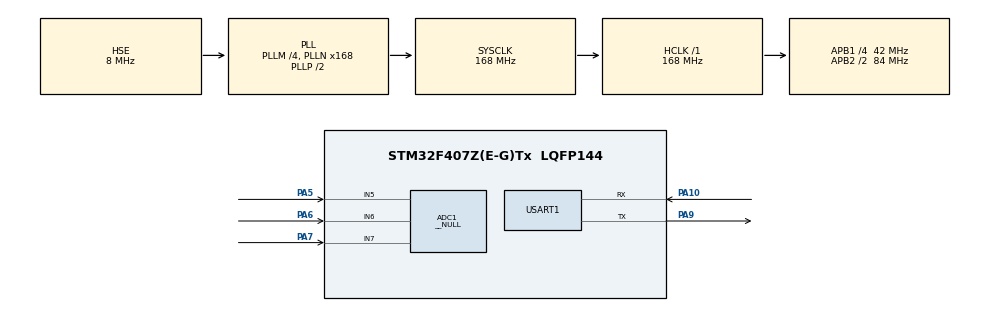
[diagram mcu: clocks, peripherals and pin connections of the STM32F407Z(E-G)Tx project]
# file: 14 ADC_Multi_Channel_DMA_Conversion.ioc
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ADC1.Channel-1\#ChannelRegularConversion=ADC_CHANNEL_5
ADC1.Channel-2\#ChannelRegularConversion=ADC_CHANNEL_6
ADC1.Channel-3\#ChannelRegularConversion=ADC_CHANNEL_7
ADC1.DMAContinuousRequests=ENABLE
ADC1.EOCSelection=ADC_EOC_SEQ_CONV
ADC1.ExternalTrigConv=ADC_EXTERNALTRIGCONV_T3_TRGO
ADC1.Mode=__NULL
ADC1.NbrOfConversion=3
ADC1.NbrOfConversionFlag=1
ADC1.Rank-1\#ChannelRegularConversion=1
ADC1.Rank-2\#ChannelRegularConversion=2
ADC1.Rank-3\#ChannelRegularConversion=3
ADC1.SamplingTime-1\#ChannelRegularConversion=ADC_SAMPLETIME_15CYCLES
ADC1.SamplingTime-2\#ChannelRegularConversion=ADC_SAMPLETIME_15CYCLES
ADC1.SamplingTime-3\#ChannelRegularConversion=ADC_SAMPLETIME_15CYCLES
ADC1.ScanConvMode=ENABLE
ADC1.master=1
Dma.ADC1.0.Direction=DMA_PERIPH_TO_MEMORY
Dma.ADC1.0.FIFOMode=DMA_FIFOMODE_DISABLE
Dma.ADC1.0.Instance=DMA2_Stream0
Dma.ADC1.0.MemDataAlignment=DMA_MDATAALIGN_WORD
Dma.ADC1.0.MemInc=DMA_MINC_ENABLE
Dma.ADC1.0.Mode=DMA_CIRCULAR
Dma.ADC1.0.PeriphDataAlignment=DMA_PDATAALIGN_WORD
Dma.ADC1.0.PeriphInc=DMA_PINC_DISABLE
Dma.ADC1.0.Priority=DMA_PRIORITY_MEDIUM
Dma.Request0=ADC1
Mcu.Family=STM32F4
Mcu.Name=STM32F407Z(E-G)Tx
Mcu.Package=LQFP144
NVIC.DMA2_Stream0_IRQn=true\:1\:0\:true\:false\:true\:true\:true\:true
NVIC.PriorityGroup=NVIC_PRIORITYGROUP_4
PA10.Mode=Asynchronous
PA10.Signal=USART1_RX
PA13.Mode=Serial_Wire
PA13.Signal=SYS_JTMS-SWDIO
PA14.Mode=Serial_Wire
PA14.Signal=SYS_JTCK-SWCLK
PA5.Signal=ADCx_IN5
PA6.Signal=ADCx_IN6
PA7.Signal=ADCx_IN7
PA9.Mode=Asynchronous
PA9.Signal=USART1_TX
PC14-OSC32_IN.Mode=LSE-External-Oscillator
PC14-OSC32_IN.Signal=RCC_OSC32_IN
PC15-OSC32_OUT.Mode=LSE-External-Oscillator
PC15-OSC32_OUT.Signal=RCC_OSC32_OUT
PH0-OSC_IN.Mode=HSE-External-Oscillator
PH0-OSC_IN.Signal=RCC_OSC_IN
PH1-OSC_OUT.Mode=HSE-External-Oscillator
PH1-OSC_OUT.Signal=RCC_OSC_OUT
ProjectManager.HeapSize=0x200
ProjectManager.StackSize=0x400
ProjectManager.TargetToolchain=MDK-ARM V5.32
RCC.48MHZClocksFreq_Value=84000000
RCC.AHBFreq_Value=168000000
RCC.APB1CLKDivider=RCC_HCLK_DIV4
RCC.APB1Freq_Value=42000000
RCC.APB1TimFreq_Value=84000000
RCC.APB2CLKDivider=RCC_HCLK_DIV2
RCC.APB2Freq_Value=84000000
RCC.APB2TimFreq_Value=168000000
RCC.CortexFreq_Value=168000000
RCC.HCLKFreq_Value=168000000
RCC.HSE_VALUE=8000000
RCC.HSI_VALUE=16000000
RCC.PLLM=4
RCC.PLLN=168
RCC.PLLSourceVirtual=RCC_PLLSOURCE_HSE
RCC.RCC_RTC_Clock_Source=RCC_RTCCLKSOURCE_LSE
RCC.RCC_RTC_Clock_SourceVirtual=RCC_RTCCLKSOURCE_LSE
RCC.SYSCLKFreq_VALUE=168000000
RCC.SYSCLKSource=RCC_SYSCLKSOURCE_PLLCLK
RCC.VCOOutputFreq_Value=336000000
SH.ADCx_IN5.0=ADC1_IN5,IN5
SH.ADCx_IN6.0=ADC1_IN6,IN6
SH.ADCx_IN7.0=ADC1_IN7,IN7
TIM3.Period=999
TIM3.Prescaler=8399
TIM3.TIM_MasterOutputTrigger=TIM_TRGO_UPDATE
USART1.VirtualMode=VM_ASYNC
VP_TIM3_VS_ClockSourceINT.Mode=Internal
board=custom

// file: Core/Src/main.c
/* USER CODE BEGIN Header */
/**
  ******************************************************************************
  * @file           : main.c
  * @brief          : Main program body
  ******************************************************************************
  * @attention
  *
  * Copyright (c) 2023 STMicroelectronics.
  * All rights reserved.
  *
  * This software is licensed under terms that can be found in the LICENSE file
  * in the root directory of this software component.
  * If no LICENSE file comes with this software, it is provided AS-IS.
  *
  ******************************************************************************
  */
/* USER CODE END Header */
#include "main.h"
#include "adc.h"
#include "dma.h"
#include "tim.h"
#include "usart.h"
#include "gpio.h"

/* USER CODE BEGIN PTD */
#include "stdio.h"

#ifdef __GNUC__
#define PUTCHAR_PROTOTYPE int __io_putchar(int ch)
#else
#define PUTCHAR_PROTOTYPE int fputc(int ch, FILE *f)
#endif
PUTCHAR_PROTOTYPE
{
      HAL_UART_Transmit(&huart1, (uint8_t *)&ch, 1, HAL_MAX_DELAY);
      return ch;
}
/* USER CODE END PTD */

/* USER CODE BEGIN PV */
uint32_t DataBuffer[BATCH_DATA_LEN];
/* USER CODE END PV */

void SystemClock_Config(void);

int main(void)
{

  /* MCU Configuration--------------------------------------------------------*/

  /* Reset of all peripherals, Initializes the Flash interface and the Systick. */
  HAL_Init();

  /* Configure the system clock */
  SystemClock_Config();

  /* Initialize all configured peripherals */
  MX_GPIO_Init();
  MX_DMA_Init();
  MX_ADC1_Init();
  MX_TIM3_Init();
  MX_USART1_UART_Init();
  /* USER CODE BEGIN 2 */
	printf("Reset\r\n");

	HAL_ADC_Start_DMA(&hadc1,DataBuffer,BATCH_DATA_LEN);
	HAL_TIM_Base_Start(&htim3);
  /* USER CODE END 2 */

  /* Infinite loop */
  while (1)
  {

  }
}

void SystemClock_Config(void)
{
  RCC_OscInitTypeDef RCC_OscInitStruct = {0};
  RCC_ClkInitTypeDef RCC_ClkInitStruct = {0};

  /** Configure the main internal regulator output voltage
  */
  __HAL_RCC_PWR_CLK_ENABLE();
  __HAL_PWR_VOLTAGESCALING_CONFIG(PWR_REGULATOR_VOLTAGE_SCALE1);

  /** Initializes the RCC Oscillators according to the specified parameters
  * in the RCC_OscInitTypeDef structure.
  */
  RCC_OscInitStruct.OscillatorType = RCC_OSCILLATORTYPE_HSE;
  RCC_OscInitStruct.HSEState = RCC_HSE_ON;
  RCC_OscInitStruct.PLL.PLLState = RCC_PLL_ON;
  RCC_OscInitStruct.PLL.PLLSource = RCC_PLLSOURCE_HSE;
  RCC_OscInitStruct.PLL.PLLM = 4;
  RCC_OscInitStruct.PLL.PLLN = 168;
  RCC_OscInitStruct.PLL.PLLP = RCC_PLLP_DIV2;
  RCC_OscInitStruct.PLL.PLLQ = 4;
  if (HAL_RCC_OscConfig(&RCC_OscInitStruct) != HAL_OK)
  {
    Error_Handler();
  }

  /** Initializes the CPU, AHB and APB buses clocks
  */
  RCC_ClkInitStruct.ClockType = RCC_CLOCKTYPE_HCLK|RCC_CLOCKTYPE_SYSCLK
                              |RCC_CLOCKTYPE_PCLK1|RCC_CLOCKTYPE_PCLK2;
  RCC_ClkInitStruct.SYSCLKSource = RCC_SYSCLKSOURCE_PLLCLK;
  RCC_ClkInitStruct.AHBCLKDivider = RCC_SYSCLK_DIV1;
  RCC_ClkInitStruct.APB1CLKDivider = RCC_HCLK_DIV4;
  RCC_ClkInitStruct.APB2CLKDivider = RCC_HCLK_DIV2;

  if (HAL_RCC_ClockConfig(&RCC_ClkInitStruct, FLASH_LATENCY_5) != HAL_OK)
  {
    Error_Handler();
  }
}

void Error_Handler(void)
{
  __disable_irq();
  while (1)
  {
  }
}
